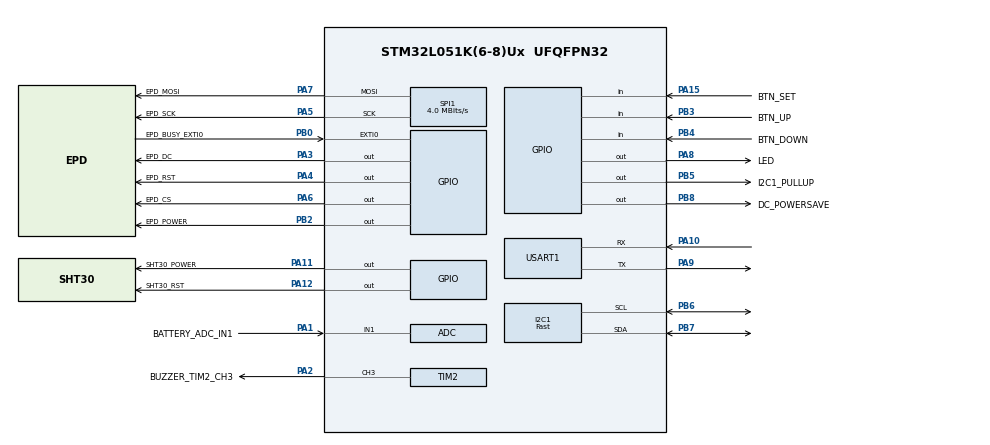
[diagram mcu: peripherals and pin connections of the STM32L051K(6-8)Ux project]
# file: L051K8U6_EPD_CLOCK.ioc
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ADC.ClockPrescaler=ADC_CLOCK_SYNC_PCLK_DIV2
ADC.EOCSelection=ADC_EOC_SINGLE_CONV
ADC.SamplingTime=ADC_SAMPLETIME_160CYCLES_5
I2C1.I2C_Coeff_DF=0
I2C1.I2C_Fall_Time=30
I2C1.I2C_Rise_Time=30
I2C1.I2C_Speed_Mode=I2C_Fast
I2C1.Timing=0x0010020B
LPTIM1.ClockPrescaler=LPTIM_PRESCALER_DIV16
Mcu.Family=STM32L0
Mcu.Name=STM32L051K(6-8)Ux
Mcu.Package=UFQFPN32
PA0.Mode=SYS_WakeUp0
PA0.Signal=SYS_WKUP1
PA1.GPIO_Label=BATTERY_ADC_IN1
PA1.Mode=IN1
PA1.Signal=ADC_IN1
PA10.Mode=Asynchronous
PA10.Signal=USART1_RX
PA11.GPIO_Label=SHT30_POWER
PA11.GPIO_ModeDefaultOutputPP=GPIO_MODE_OUTPUT_PP
PA11.GPIO_PuPd=GPIO_NOPULL
PA11.PinState=GPIO_PIN_SET
PA11.Signal=GPIO_Output
PA12.GPIO_Label=SHT30_RST
PA12.GPIO_ModeDefaultOutputPP=GPIO_MODE_OUTPUT_PP
PA12.GPIO_PuPd=GPIO_NOPULL
PA12.PinState=GPIO_PIN_RESET
PA12.Signal=GPIO_Output
PA13.Mode=Serial_Wire
PA13.Signal=SYS_SWDIO
PA14.Mode=Serial_Wire
PA14.Signal=SYS_SWCLK
PA15.GPIO_Label=BTN_SET
PA15.Signal=GPIO_Input
PA2.GPIO_Label=BUZZER_TIM2_CH3
PA2.Signal=S_TIM2_CH3
PA3.GPIO_Label=EPD_DC
PA3.GPIO_ModeDefaultOutputPP=GPIO_MODE_OUTPUT_PP
PA3.GPIO_PuPd=GPIO_NOPULL
PA3.GPIO_Speed=GPIO_SPEED_FREQ_VERY_HIGH
PA3.PinState=GPIO_PIN_RESET
PA3.Signal=GPIO_Output
PA4.GPIO_Label=EPD_RST
PA4.GPIO_ModeDefaultOutputPP=GPIO_MODE_OUTPUT_PP
PA4.GPIO_PuPd=GPIO_NOPULL
PA4.PinState=GPIO_PIN_RESET
PA4.Signal=GPIO_Output
PA5.GPIO_Label=EPD_SCK
PA5.Mode=TX_Only_Simplex_Unidirect_Master
PA5.Signal=SPI1_SCK
PA6.GPIO_Label=EPD_CS
PA6.GPIO_ModeDefaultOutputPP=GPIO_MODE_OUTPUT_PP
PA6.GPIO_PuPd=GPIO_NOPULL
PA6.GPIO_Speed=GPIO_SPEED_FREQ_VERY_HIGH
PA6.PinState=GPIO_PIN_RESET
PA6.Signal=GPIO_Output
PA7.GPIO_Label=EPD_MOSI
PA7.Mode=TX_Only_Simplex_Unidirect_Master
PA7.Signal=SPI1_MOSI
PA8.GPIO_Label=LED
PA8.GPIO_ModeDefaultOutputPP=GPIO_MODE_OUTPUT_PP
PA8.GPIO_PuPd=GPIO_NOPULL
PA8.PinState=GPIO_PIN_SET
PA8.Signal=GPIO_Output
PA9.Mode=Asynchronous
PA9.Signal=USART1_TX
PB0.GPIO_Label=EPD_BUSY_EXTI0
PB0.GPIO_ModeDefaultEXTI=GPIO_MODE_IT_FALLING
PB0.GPIO_PuPd=GPIO_PULLDOWN
PB0.Signal=GPXTI0
PB1.Mode=VREFINT_ADC_PB1
PB1.Signal=SYS_VREF_OUT_PB1
PB2.GPIO_Label=EPD_POWER
PB2.GPIO_ModeDefaultOutputPP=GPIO_MODE_OUTPUT_PP
PB2.GPIO_PuPd=GPIO_NOPULL
PB2.PinState=GPIO_PIN_SET
PB2.Signal=GPIO_Output
PB3.GPIO_Label=BTN_UP
PB3.Signal=GPIO_Input
PB4.GPIO_Label=BTN_DOWN
PB4.Signal=GPIO_Input
PB5.GPIO_Label=I2C1_PULLUP
PB5.GPIO_ModeDefaultOutputPP=GPIO_MODE_OUTPUT_PP
PB5.GPIO_PuPd=GPIO_NOPULL
PB5.PinState=GPIO_PIN_RESET
PB5.Signal=GPIO_Output
PB6.Mode=I2C
PB6.Signal=I2C1_SCL
PB7.Mode=I2C
PB7.Signal=I2C1_SDA
PB8.GPIO_Label=DC_POWERSAVE
PB8.PinState=GPIO_PIN_RESET
PB8.Signal=GPIO_Output
ProjectManager.HeapSize=0x000
ProjectManager.StackSize=0x400
ProjectManager.TargetToolchain=MDK-ARM V5.27
RCC.AHBCLKDivider=RCC_SYSCLK_DIV2
RCC.AHBFreq_Value=8000000
RCC.APB1Freq_Value=8000000
RCC.APB1TimFreq_Value=8000000
RCC.APB2Freq_Value=8000000
RCC.APB2TimFreq_Value=8000000
RCC.HCLKFreq_Value=8000000
RCC.HSI16_VALUE=16000000
RCC.HSI_VALUE=16000000
RCC.LSE_VALUE=32768
RCC.LptimClockSelection=RCC_LPTIM1CLKSOURCE_LSI
RCC.MSI_VALUE=2097000
RCC.PREFETCH_ENABLE=0
RCC.SYSCLKFreq_VALUE=16000000
RCC.SYSCLKSource=RCC_SYSCLKSOURCE_HSI
RCC.VCOOutputFreq_Value=48000000
SH.S_TIM2_CH3.0=TIM2_CH3,PWM Generation3 CH3
SPI1.BaudRatePrescaler=SPI_BAUDRATEPRESCALER_2
SPI1.CLKPhase=SPI_PHASE_2EDGE
SPI1.CLKPolarity=SPI_POLARITY_HIGH
SPI1.CalculateBaudRate=4.0 MBits/s
SPI1.Direction=SPI_DIRECTION_2LINES
SPI1.Mode=SPI_MODE_MASTER
SPI1.VirtualType=VM_MASTER
TIM2.Channel-PWM\ Generation3\ CH3=TIM_CHANNEL_3
TIM2.OCPolarity_3=TIM_OCPOLARITY_LOW
TIM2.Period=249
TIM2.Prescaler=7
TIM2.Pulse-PWM\ Generation3\ CH3=124
USART1.VirtualMode-Asynchronous=VM_ASYNC
VP_ADC_TempSens_Input.Mode=IN-TempSens
VP_ADC_Vref_Input.Mode=IN-Vrefint
VP_LPTIM1_VS_LPTIM_counterModeInternalClock.Mode=Counts__internal_clock_event_00
VP_TIM2_VS_ClockSourceINT.Mode=Internal
board=custom

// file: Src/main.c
/* USER CODE BEGIN Header */
/**
  ******************************************************************************
  * @file           : main.c
  * @brief          : Main program body
  ******************************************************************************
  * @attention
  *
  * <h2><center>&copy; Copyright (c) 2020 STMicroelectronics.
  * All rights reserved.</center></h2>
  *
  * This software component is licensed by ST under BSD 3-Clause license,
  * the "License"; You may not use this file except in compliance with the
  * License. You may obtain a copy of the License at:
  *                        opensource.org/licenses/BSD-3-Clause
  *
  ******************************************************************************
  */
/* USER CODE END Header */
#include "main.h"
#include "adc.h"
#include "i2c.h"
#include "lptim.h"
#include "spi.h"
#include "tim.h"
#include "usart.h"
#include "gpio.h"

/* USER CODE BEGIN Includes */
#include "func.h"
/* USER CODE END Includes */

void SystemClock_Config(void);

int main(void)
{

  /* MCU Configuration--------------------------------------------------------*/

  /* Reset of all peripherals, Initializes the Flash interface and the Systick. */

  LL_APB2_GRP1_EnableClock(LL_APB2_GRP1_PERIPH_SYSCFG);
  LL_APB1_GRP1_EnableClock(LL_APB1_GRP1_PERIPH_PWR);

  /* System interrupt init*/

  /** Select which pad is connected to VREFINT_ADC
  */
  LL_SYSCFG_VREFINT_SetConnection(LL_SYSCFG_VREFINT_CONNECT_IO2);

  /* Configure the system clock */
  SystemClock_Config();

  /* Initialize all configured peripherals */
  MX_GPIO_Init();
  MX_ADC_Init();
  MX_I2C1_Init();
  MX_SPI1_Init();
  MX_USART1_UART_Init();
  MX_TIM2_Init();
  MX_LPTIM1_Init();
  /* USER CODE BEGIN 2 */
  Init();
  /* USER CODE END 2 */

  /* Infinite loop */
  /* USER CODE BEGIN WHILE */
  while (1)
  {
    for (;;)
    {
      Loop();
    }
    /* USER CODE END WHILE */

  }
}

void SystemClock_Config(void)
{
  LL_FLASH_SetLatency(LL_FLASH_LATENCY_0);
  while(LL_FLASH_GetLatency()!= LL_FLASH_LATENCY_0)
  {
  }
  LL_PWR_SetRegulVoltageScaling(LL_PWR_REGU_VOLTAGE_SCALE1);
  LL_RCC_HSI_Enable();

   /* Wait till HSI is ready */
  while(LL_RCC_HSI_IsReady() != 1)
  {

  }
  LL_RCC_HSI_SetCalibTrimming(16);
  LL_RCC_LSI_Enable();

   /* Wait till LSI is ready */
  while(LL_RCC_LSI_IsReady() != 1)
  {

  }
  LL_RCC_SetAHBPrescaler(LL_RCC_SYSCLK_DIV_2);
  LL_RCC_SetAPB1Prescaler(LL_RCC_APB1_DIV_1);
  LL_RCC_SetAPB2Prescaler(LL_RCC_APB2_DIV_1);
  LL_RCC_SetSysClkSource(LL_RCC_SYS_CLKSOURCE_HSI);

   /* Wait till System clock is ready */
  while(LL_RCC_GetSysClkSource() != LL_RCC_SYS_CLKSOURCE_STATUS_HSI)
  {

  }

  LL_Init1msTick(8000000);

  LL_SetSystemCoreClock(8000000);
  LL_RCC_SetUSARTClockSource(LL_RCC_USART1_CLKSOURCE_PCLK2);
  LL_RCC_SetI2CClockSource(LL_RCC_I2C1_CLKSOURCE_PCLK1);
  LL_RCC_SetLPTIMClockSource(LL_RCC_LPTIM1_CLKSOURCE_LSI);
}

void Error_Handler(void)
{
}

/************************ (C) COPYRIGHT STMicroelectronics *****END OF FILE****/
